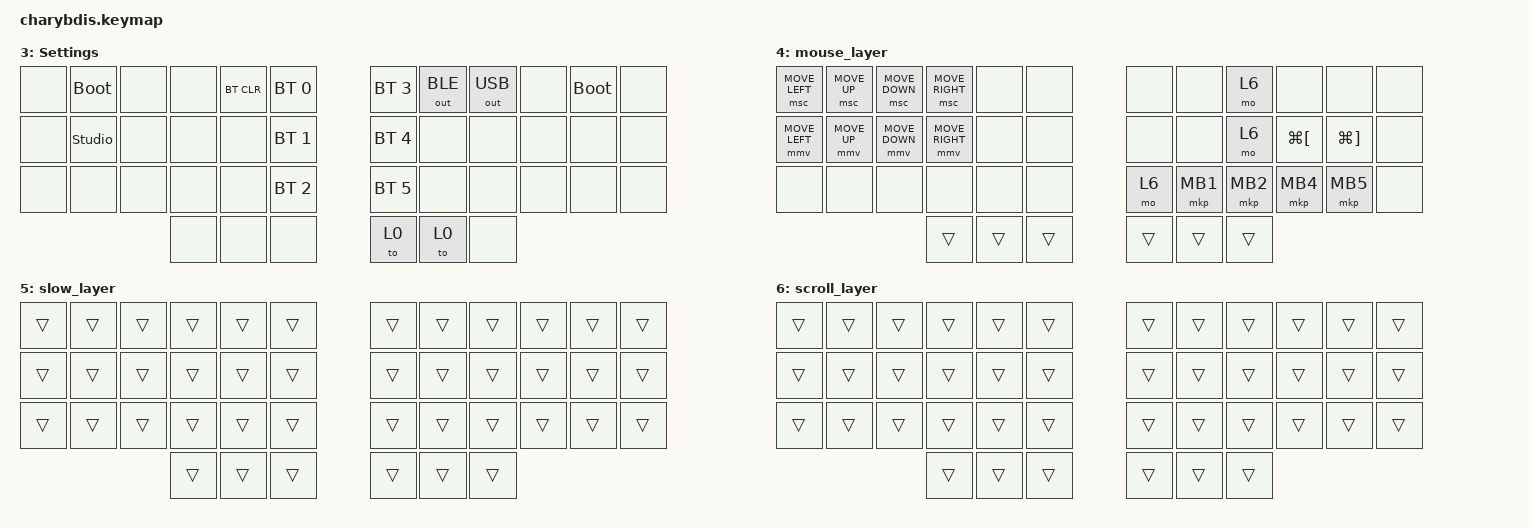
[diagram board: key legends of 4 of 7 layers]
#include <behaviors.dtsi>
#include <dt-bindings/zmk/matrix_transform.h>
#include <dt-bindings/zmk/keys.h>
#include <dt-bindings/zmk/bt.h>
#include <dt-bindings/zmk/mouse.h>
#include <dt-bindings/zmk/outputs.h>
#include <behaviors/mouse_keys.dtsi>
#include <dt-bindings/zmk/ext_power.h>
#include "macros.dtsi"
#include "behaviors.dtsi"
#include "combos.dtsi"

// Layer definitions
#define BASE 0
#define SYM 1
#define NAV 2
#define SETTINGS 3
#define MOUSE 4
#define SLOW 5
#define SCROLL 6

// Add your additional behaviors
&sk {
    // don't release mods on other mods presses
    ignore-modifiers;
};

/ {
    /* input config for mouse move mode */
    trackball_listener {
        compatible = "zmk,input-behavior-listener";
        device = <&vtrackball>;
        layers = <0 1 2 3 4>;
        evt-type = <INPUT_EV_REL>;
        x-input-code = <INPUT_REL_X>;
        y-input-code = <INPUT_REL_Y>;
        scale-multiplier = <4>;
        scale-divisor = <5>;
        // bindings = <&ib_toggle_layer 7>;
    };

    /* input config for snipe mode */
    trackball_snipe_listener {
        compatible = "zmk,input-behavior-listener";
        device = <&vtrackball>;
        layers = <5>;
        evt-type = <INPUT_EV_REL>;
        x-input-code = <INPUT_REL_X>;
        y-input-code = <INPUT_REL_Y>;
        scale-multiplier = <1>;
        scale-divisor = <6>;
    };

    /* input config for mouse scroll mode */
    trackball_scroll_listener {
        compatible = "zmk,input-behavior-listener";
        device = <&vtrackball>;
        layers = <6>;
        evt-type = <INPUT_EV_REL>;
        x-input-code = <INPUT_REL_MISC>;
        y-input-code = <INPUT_REL_WHEEL>;
        y-invert;
        bindings = <&ib_wheel_scaler 1 14>;
    };

    /* define a resolution down scaler only for INPUT_REL_WHEEL */
    ib_wheel_scaler: ib_wheel_scaler {
        compatible = "zmk,input-behavior-scaler";
        #binding-cells = <2>;
        evt-type = <INPUT_EV_REL>;
        input-code = <INPUT_REL_WHEEL>;
    };

    /* adjust cooldown waiting period for mouse key layer after activated */
    ib_toggle_layer: ib_toggle_layer {
        compatible = "zmk,input-behavior-tog-layer";
        #binding-cells = <1>;
        time-to-live-ms = <750>;
    };


// ╭──────┬──────┬──────┬──────┬──────┬──────╮  ╭──────┬──────┬──────┬──────┬──────┬──────╮
//    00     01     02     03    04      05        06     07     08     09     10     11
// ├──────┼──────┼──────┼──────┼──────┼──────┤  ├──────┼──────┼──────┼──────┼──────┼──────┤
//    12     13     14     15    16      17        18     19     20     21     22     23
// ├──────┼──────┼──────┼──────┼──────┼──────┤  ├──────┼──────┼──────┼──────┼──────┼──────┤
//    24     25     26     27    28      29        30     31     32     33     34     35
// ╰──────┴──────┴──────┼──────┼──────┼──────┤  ├──────┼──────┼──────┴──────┴──────┴──────╯
//                         36     37     38        39     40
//                      ╰──────┴──────┴──────╯  ╰──────┴──────╯

    keymap {
        compatible = "zmk,keymap";

        default_layer {
            label = "Base";
            bindings = <
// ╭──────────────┬────────────┬─────────────┬────────────┬────────────┬────────────╮  ╭────────────┬────────────┬────────────┬────────────┬───────────────┬──────────────╮
    &none          &kp V         &kp W         &kp G         &kp M         &kp J        &kp SEMICOLON &kp COMMA    &kp PERIOD   &kp MINUS    &kp EQUAL       &none
// ├──────────────┼────────────┼─────────────┼────────────┼────────────┼────────────┤  ├────────────┼────────────┼────────────┼────────────┼───────────────┼──────────────┤
    &none          &hm LCTRL S   &hm LSHIFT N  &hm LGUI T  &hm LALT H    &kp K     &kp SLASH    &hm RALT A    &hm RGUI E    &hm RSHIFT I  &hm RCTRL C     &none
// ├──────────────┼────────────┼─────────────┼────────────┼────────────┼────────────┤  ├────────────┼────────────┼────────────┼────────────┼───────────────┼──────────────┤
    &none          &kp P         &kp F         &lt 6 D       &lt 4 L      &kp X         &kp SQT  &kp U        &kp O      &kp Y         &kp B           &none
// ╰──────────────┴────────────┴─────────────┼────────────┼────────────┼────────────┤  ├────────────┼────────────┼────────────┴────────────┴───────────────┴──────────────╯
                                               &lt 1 R      &lt 2 BSPC   &mkp LCLK       &lt 2 TAB		&td_space
//                                           ╰────────────┴────────────┴────────────╯  ╰────────────┴────────────┴

            >;
        };

        sym_layer {
            label = "Sym";
            bindings = <
// ╭────────┬────────┬────────┬────────┬────────┬────────╮  ╭────────┬────────┬────────┬────────┬────────┬────────╮
    &none     &kp EXCL  &kp AT    &kp HASH  &kp LBRC  &kp RBRC    &kp ASTRK &kp N7    &kp N8    &kp N9    &kp CAPS  &none
// ├────────┼────────┼────────┼────────┼────────┼────────┤  ├────────┼────────┼────────┼────────┼────────┼────────┤
    &none     &kp CARET &kp TILDE &kp GRAVE &kp LBKT  &kp RBKT    &kp BSLH  &kp N4    &kp N5    &kp N6    &caps_word &none
// ├────────┼────────┼────────┼────────┼────────┼────────┤  ├────────┼────────┼────────┼────────┼────────┼────────┤
    &none     &kp DLLR  &kp PIPE  &kp AMPS  &kp LPAR  &kp RPAR    &kp N0    &kp N1    &kp N2    &kp N3    &kp PRCNT &none
// ╰────────┴────────┴────────┼────────┼────────┼────────┤  ├────────┼────────┼────────┴────────┴────────┴────────╯
                                 &trans    &trans    &trans       &trans    &trans
//                            ╰────────┴────────┴────────╯  ╰────────┴────────┴────────╯
            >;
        };

        nav_layer {
            label = "Nav";
            bindings = <
// ╭────────┬────────┬────────────┬──────────┬──────────┬────────╮  ╭───────────────┬───────────────┬────────┬────────┬────────┬────────╮
    &none     &trans   &kp C_PREV   &kp C_PP   &kp C_NEXT  &trans     &kp PG_UP       &kp HOME        &kp UP   &kp END  &trans    &none
// ├────────┼────────┼────────────┼──────────┼──────────┼────────┤  ├───────────────┼───────────────┼────────┼────────┼────────┼────────┤
    &none     &trans   &kp C_MUTE   &kp C_VOL_DN &kp C_VOL_UP &trans  &kp PG_DN       &kp LEFT        &kp DOWN &kp RIGHT &trans    &none
// ├────────┼────────┼────────────┼──────────┼──────────┼────────┤  ├───────────────┼───────────────┼────────┼────────┼────────┼────────┤
    &none     &trans   &trans       &kp LG(C)  &kp LG(V) &kp LG(X)    &kp C_BRI_INC   &kp C_BRI_DEC   &trans   &trans   &trans    &none
// ╰────────┴────────┴────────────┼──────────┼──────────┼────────┤  ├───────────────┼───────────────┼────────┴────────┴────────┴────────╯
                                    &none     &none       &none      &none     &none
//                                ╰──────────┴──────────┴────────╯  ╰────────┴────────┴────────╯
            >;
        };


        settings_layer {
            label = "Settings";
            bindings = <
// ╭────────┬────────────┬────────┬────────┬─────────┬────────╮  ╭────────────┬────────┬────────┬─────────┬────────┬────────╮
    &none     &bootloader  &none     &none     &bt BT_CLR &bt BT_SEL 0  &bt BT_SEL 3 &out OUT_BLE &out OUT_USB &none &bootloader &none
// ├────────┼────────────┼────────┼────────┼─────────┼────────┤  ├────────────┼────────┼────────┼─────────┼────────┼────────┤
    &none    &studio_unlock &none     &none     &none      &bt BT_SEL 1  &bt BT_SEL 4 &none     &none     &none     &none       &none
// ├────────┼────────────┼────────┼────────┼─────────┼────────┤  ├────────────┼────────┼────────┼─────────┼────────┼────────┤
    &none     &none        &none     &none     &none      &bt BT_SEL 2  &bt BT_SEL 5 &none     &none     &none     &none       &none
// ╰────────┴────────────┴────────┼────────┼─────────┼────────┤  ├────────────┼────────┼────────┴─────────┴────────┴────────╯
                                     &none     &none      &none        &to 0        &to 0     &none
//                                ╰────────┴─────────┴────────╯  ╰────────────┴────────┴────────╯
            >;

        };

mouse_layer {
    bindings = <
// ╭─────┬───────┬────────┬───────┬───────┬──────╮  ╭───────┬──────────────┬──────────────┬──────────────┬──────────────┬────────────╮
    &msc MOVE_LEFT &msc MOVE_UP   &msc MOVE_DOWN &msc MOVE_RIGHT &none &none &none  &none   &mo 6   &none   &none  &none
// ├─────┼───────┼────────┼───────┼───────┼──────┤  ├───────┼──────────────┼──────────────┼──────────────┼──────────────┼────────────┤
    &mmv MOVE_LEFT &mmv MOVE_UP   &mmv MOVE_DOWN &mmv MOVE_RIGHT &none &none &none  &none &mo 6 &kp LG(LEFT_BRACKET) &kp LG(RIGHT_BRACKET) &none
// ├─────┼───────┼────────┼───────┼───────┼──────┤  ├───────┼──────────────┼──────────────┼──────────────┼──────────────┼────────────┤
    &none  &none   &none    &none   &none  &none      &mo 6  &mkp MB1      &mkp MB2   &mkp MB4       &mkp MB5       &none
// ╰─────┴───────┴────────┼───────┼───────┼──────┤  ├───────┼──────────────┼────────┴────────┴────────┴────────╯
                          &trans  &trans   &trans    &trans   &trans  &trans
//                       ╰──────┴────────┴───────╯  ╰───────┴────────┴────────╯
    >;
};

        slow_layer {
            bindings = <
// ╭────────┬────────┬────────┬────────┬────────┬────────╮  ╭────────┬────────┬────────┬────────┬────────┬────────╮
    &trans    &trans    &trans    &trans    &trans    &trans      &trans    &trans    &trans    &trans    &trans    &trans
// ├────────┼────────┼────────┼────────┼────────┼────────┤  ├────────┼────────┼────────┼────────┼────────┼────────┤
    &trans    &trans    &trans    &trans    &trans    &trans      &trans    &trans    &trans    &trans    &trans    &trans
// ├────────┼────────┼────────┼────────┼────────┼────────┤  ├────────┼────────┼────────┼────────┼────────┼────────┤
    &trans    &trans    &trans    &trans    &trans    &trans      &trans    &trans    &trans    &trans    &trans    &trans
// ╰────────┴────────┴────────┼────────┼────────┼────────┤  ├────────┼────────┼────────┴────────┴────────┴────────╯
                                 &trans    &trans    &trans      &trans    &trans    &trans
//                            ╰────────┴────────┴────────╯  ╰────────┴────────┴────────╯
            >;
        };

        scroll_layer {
            bindings = <
// ╭────────┬────────┬────────┬────────┬────────┬────────╮  ╭────────┬────────┬────────┬────────┬────────┬────────╮
    &trans    &trans    &trans    &trans    &trans    &trans      &trans    &trans    &trans    &trans    &trans    &trans
// ├────────┼────────┼────────┼────────┼────────┼────────┤  ├────────┼────────┼────────┼────────┼────────┼────────┤
    &trans    &trans    &trans    &trans    &trans    &trans      &trans    &trans    &trans    &trans    &trans    &trans
// ├────────┼────────┼────────┼────────┼────────┼────────┤  ├────────┼────────┼────────┼────────┼────────┼────────┤
    &trans    &trans    &trans    &trans    &trans    &trans      &trans    &trans    &trans    &trans    &trans    &trans
// ╰────────┴────────┴────────┼────────┼────────┼────────┤  ├────────┼────────┼────────┴────────┴────────┴────────╯
                                 &trans    &trans    &trans      &trans    &trans    &trans
//                            ╰────────┴────────┴────────╯  ╰────────┴────────┴────────╯
            >;
        };
    };
};
